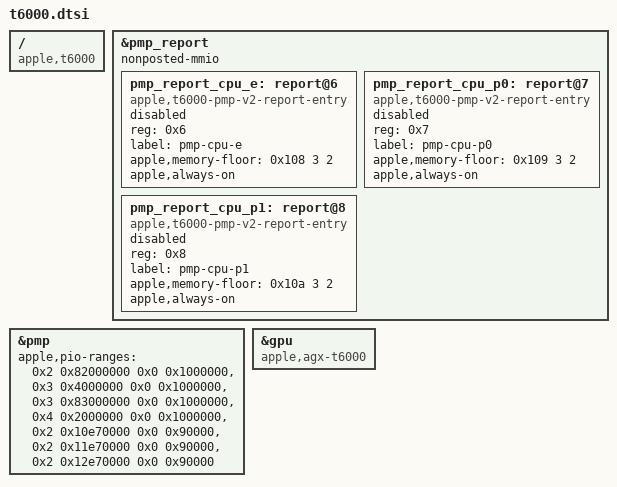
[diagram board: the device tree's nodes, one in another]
// SPDX-License-Identifier: GPL-2.0+ OR MIT
/*
 * Apple T6000 "M1 Pro" SoC
 *
 * Other names: H13J, "Jade Chop"
 *
 * Copyright The Asahi Linux Contributors
 */

/* This chip is just a cut down version of t6001, so include it and disable the missing parts */

#define GPU_REPEAT(x) <x x>

#include "t6001.dtsi"

/ {
	compatible = "apple,t6000", "apple,arm-platform";
};

/delete-node/ &pmgr_south;
/delete-node/ &pmp_report_dispext2;
/delete-node/ &pmp_report_dispext3;
/delete-node/ &pmp_report_venc1;
/delete-node/ &pmp_report_msr1;
/delete-node/ &pmp_report_prores;
/delete-node/ &pmp_report_afnc4_ioa;
/delete-node/ &pmp_report_afnc5_ioa;

&pmp_report {
	nonposted-mmio;

	/* Experimental, default-off shared-memory floors for CPU clients. */
	pmp_report_cpu_e: report@6 {
		compatible = "apple,t6000-pmp-v2-report-entry";
		reg = <0x6>;
		label = "pmp-cpu-e";
		#power-domain-cells = <0>;
		apple,memory-floor = <0x108 3 2>;
		apple,always-on;
		status = "disabled";
	};

	pmp_report_cpu_p0: report@7 {
		compatible = "apple,t6000-pmp-v2-report-entry";
		reg = <0x7>;
		label = "pmp-cpu-p0";
		#power-domain-cells = <0>;
		apple,memory-floor = <0x109 3 2>;
		apple,always-on;
		status = "disabled";
	};

	pmp_report_cpu_p1: report@8 {
		compatible = "apple,t6000-pmp-v2-report-entry";
		reg = <0x8>;
		label = "pmp-cpu-p1";
		#power-domain-cells = <0>;
		apple,memory-floor = <0x10a 3 2>;
		apple,always-on;
		status = "disabled";
	};
};

&pmp {
	apple,pio-ranges = <0x2 0x82000000 0x0 0x1000000>,
		<0x3 0x4000000 0x0 0x1000000>,
		<0x3 0x83000000 0x0 0x1000000>,
		<0x4 0x2000000 0x0 0x1000000>,
		<0x2 0x10e70000 0x0 0x90000>,
		<0x2 0x11e70000 0x0 0x90000>,
		<0x2 0x12e70000 0x0 0x90000>;
};

&gpu {
	compatible = "apple,agx-t6000", "apple,agx-g13x";
};
